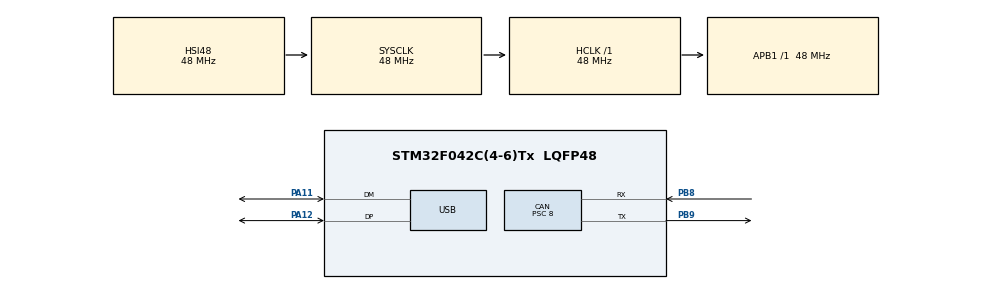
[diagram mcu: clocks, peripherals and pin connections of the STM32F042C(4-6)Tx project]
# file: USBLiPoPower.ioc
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CAN.BS1=CAN_BS1_4TQ
CAN.CalculateBaudRate=1000000
CAN.CalculateTimeBit=1000
CAN.CalculateTimeQuantum=166.66666666666666
CAN.Prescaler=8
IWDG.Prescaler=IWDG_PRESCALER_32
Mcu.Family=STM32F0
Mcu.Name=STM32F042C(4-6)Tx
Mcu.Package=LQFP48
NVIC.CEC_CAN_IRQn=true\:1\:0\:true\:false\:true\:true\:true\:true
NVIC.USB_IRQn=true\:0\:0\:false\:false\:true\:false\:true\:true
PA11.Mode=Device
PA11.Signal=USB_DM
PA12.Mode=Device
PA12.Signal=USB_DP
PB8.GPIO_PuPd=GPIO_PULLUP
PB8.Mode=CAN_Activate
PB8.Signal=CAN_RX
PB9.Mode=CAN_Activate
PB9.Signal=CAN_TX
ProjectManager.HeapSize=0x200
ProjectManager.StackSize=0x400
ProjectManager.TargetToolchain=STM32CubeIDE
RCC.AHBFreq_Value=48000000
RCC.APB1Freq_Value=48000000
RCC.APB1TimFreq_Value=48000000
RCC.HCLKFreq_Value=48000000
RCC.SYSCLKFreq_VALUE=48000000
RCC.SYSCLKSource=RCC_SYSCLKSOURCE_HSI48
USB_DEVICE.APP_RX_DATA_SIZE=256
USB_DEVICE.APP_TX_DATA_SIZE=1024
USB_DEVICE.CLASS_NAME_FS=CDC
USB_DEVICE.VirtualMode=Cdc
USB_DEVICE.VirtualModeFS=Cdc_FS
VP_IWDG_VS_IWDG.Mode=IWDG_Activate
VP_RCC_USB.Mode=CRS SYNC Source USB
VP_USB_DEVICE_VS_USB_DEVICE_CDC_FS.Mode=CDC_FS
board=custom

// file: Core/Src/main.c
/* USER CODE BEGIN Header */
/**
  ******************************************************************************
  * @file           : main.c
  * @brief          : Main program body
  ******************************************************************************
  * @attention
  *
  * <h2><center>&copy; Copyright (c) 2020 STMicroelectronics.
  * All rights reserved.</center></h2>
  *
  * This software component is licensed by ST under BSD 3-Clause license,
  * the "License"; You may not use this file except in compliance with the
  * License. You may obtain a copy of the License at:
  *                        opensource.org/licenses/BSD-3-Clause
  *
  ******************************************************************************
  */
/* USER CODE END Header */
#include "main.h"
#include "usb_device.h"

/* USER CODE BEGIN Includes */
#include "app.h"

//#include "usbd_cdc_if.h"

/* USER CODE END Includes */

CAN_HandleTypeDef hcan;

IWDG_HandleTypeDef hiwdg;

void SystemClock_Config(void);
static void MX_GPIO_Init(void);
static void MX_CAN_Init(void);
static void MX_IWDG_Init(void);

/* USER CODE BEGIN 0 */

//#define DBG

extern void initialise_monitor_handles(void);

/* USER CODE END 0 */

int main(void)
{
  /* USER CODE BEGIN 1 */

#ifdef DEBUG
	initialise_monitor_handles();
#endif

  /* USER CODE END 1 */

  /* MCU Configuration--------------------------------------------------------*/

  /* Reset of all peripherals, Initializes the Flash interface and the Systick. */
  HAL_Init();

  /* Configure the system clock */
  SystemClock_Config();

  /* Initialize all configured peripherals */
  MX_GPIO_Init();
  MX_CAN_Init();
  MX_USB_DEVICE_Init();
  MX_IWDG_Init();
  /* USER CODE BEGIN 2 */

  setup();

  /* USER CODE END 2 */

  /* Infinite loop */
  while (1)
  {

    /* USER CODE BEGIN 3 */

    loop();

#ifndef DEBUG
    HAL_IWDG_Refresh(&hiwdg);
#endif
  }
  /* USER CODE END 3 */
}

void SystemClock_Config(void)
{
  RCC_OscInitTypeDef RCC_OscInitStruct = {0};
  RCC_ClkInitTypeDef RCC_ClkInitStruct = {0};
  RCC_PeriphCLKInitTypeDef PeriphClkInit = {0};
  RCC_CRSInitTypeDef RCC_CRSInitStruct = {0};

  /** Initializes the RCC Oscillators according to the specified parameters
  * in the RCC_OscInitTypeDef structure.
  */
  RCC_OscInitStruct.OscillatorType = RCC_OSCILLATORTYPE_HSI48|RCC_OSCILLATORTYPE_LSI;
  RCC_OscInitStruct.HSI48State = RCC_HSI48_ON;
  RCC_OscInitStruct.LSIState = RCC_LSI_ON;
  RCC_OscInitStruct.PLL.PLLState = RCC_PLL_NONE;
  if (HAL_RCC_OscConfig(&RCC_OscInitStruct) != HAL_OK)
  {
    Error_Handler();
  }

  /** Initializes the CPU, AHB and APB buses clocks
  */
  RCC_ClkInitStruct.ClockType = RCC_CLOCKTYPE_HCLK|RCC_CLOCKTYPE_SYSCLK
                              |RCC_CLOCKTYPE_PCLK1;
  RCC_ClkInitStruct.SYSCLKSource = RCC_SYSCLKSOURCE_HSI48;
  RCC_ClkInitStruct.AHBCLKDivider = RCC_SYSCLK_DIV1;
  RCC_ClkInitStruct.APB1CLKDivider = RCC_HCLK_DIV1;

  if (HAL_RCC_ClockConfig(&RCC_ClkInitStruct, FLASH_LATENCY_1) != HAL_OK)
  {
    Error_Handler();
  }
  PeriphClkInit.PeriphClockSelection = RCC_PERIPHCLK_USB;
  PeriphClkInit.UsbClockSelection = RCC_USBCLKSOURCE_HSI48;

  if (HAL_RCCEx_PeriphCLKConfig(&PeriphClkInit) != HAL_OK)
  {
    Error_Handler();
  }

  /** Enable the SYSCFG APB clock
  */
  __HAL_RCC_CRS_CLK_ENABLE();

  /** Configures CRS
  */
  RCC_CRSInitStruct.Prescaler = RCC_CRS_SYNC_DIV1;
  RCC_CRSInitStruct.Source = RCC_CRS_SYNC_SOURCE_USB;
  RCC_CRSInitStruct.Polarity = RCC_CRS_SYNC_POLARITY_RISING;
  RCC_CRSInitStruct.ReloadValue = __HAL_RCC_CRS_RELOADVALUE_CALCULATE(48000000,1000);
  RCC_CRSInitStruct.ErrorLimitValue = 34;
  RCC_CRSInitStruct.HSI48CalibrationValue = 32;

  HAL_RCCEx_CRSConfig(&RCC_CRSInitStruct);
}

static void MX_CAN_Init(void)
{

  hcan.Instance = CAN;
  hcan.Init.Prescaler = 8;
  hcan.Init.Mode = CAN_MODE_NORMAL;
  hcan.Init.SyncJumpWidth = CAN_SJW_1TQ;
  hcan.Init.TimeSeg1 = CAN_BS1_4TQ;
  hcan.Init.TimeSeg2 = CAN_BS2_1TQ;
  hcan.Init.TimeTriggeredMode = DISABLE;
  hcan.Init.AutoBusOff = DISABLE;
  hcan.Init.AutoWakeUp = DISABLE;
  hcan.Init.AutoRetransmission = DISABLE;
  hcan.Init.ReceiveFifoLocked = DISABLE;
  hcan.Init.TransmitFifoPriority = DISABLE;
  if (HAL_CAN_Init(&hcan) != HAL_OK)
  {
    Error_Handler();
  }

}

static void MX_IWDG_Init(void)
{

  /* USER CODE BEGIN IWDG_Init 0 */
#ifdef DEBUG
  return;
#endif
  /* USER CODE END IWDG_Init 0 */

  hiwdg.Instance = IWDG;
  hiwdg.Init.Prescaler = IWDG_PRESCALER_32;
  hiwdg.Init.Window = 4095;
  hiwdg.Init.Reload = 4095;
  if (HAL_IWDG_Init(&hiwdg) != HAL_OK)
  {
    Error_Handler();
  }

}

static void MX_GPIO_Init(void)
{

  /* GPIO Ports Clock Enable */
  __HAL_RCC_GPIOA_CLK_ENABLE();
  __HAL_RCC_GPIOB_CLK_ENABLE();

}

void Error_Handler(void)
{
}
